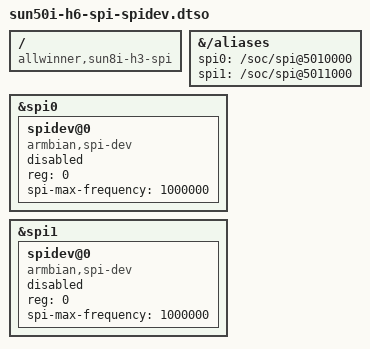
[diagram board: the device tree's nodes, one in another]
/dts-v1/;
/plugin/;

/ {
	compatible = "allwinner,sun8i-h3-spi";

	fragment@0 {
		target-path = "/aliases";
		__overlay__ {
			spi0 = "/soc/spi@5010000";
			spi1 = "/soc/spi@5011000";
		};
	};

	fragment@1 {
		target = <&spi0>;
		__overlay__ {
			#address-cells = <1>;
			#size-cells = <0>;
			spidev@0 {
				compatible = "armbian,spi-dev";
				status = "disabled";
				reg = <0>;
				spi-max-frequency = <1000000>;
			};
		};
	};

	fragment@2 {
		target = <&spi1>;
		__overlay__ {
			#address-cells = <1>;
			#size-cells = <0>;
			spidev@0 {
				compatible = "armbian,spi-dev";
				status = "disabled";
				reg = <0>;
				spi-max-frequency = <1000000>;
			};
		};
	};
};
